# TLE986x register map
File version: 2.5
Registers are 32-bit, read-write, reset 0x0 unless marked. A register's access mark holds for its fields unless they carry their own. Offsets are from the block's base; [hi:lo] are bit positions; {n}, {i} and the like mark numbered series; 'fields as' and 'values as' point back to an identical list.

## BDRV
Base 0x40034000
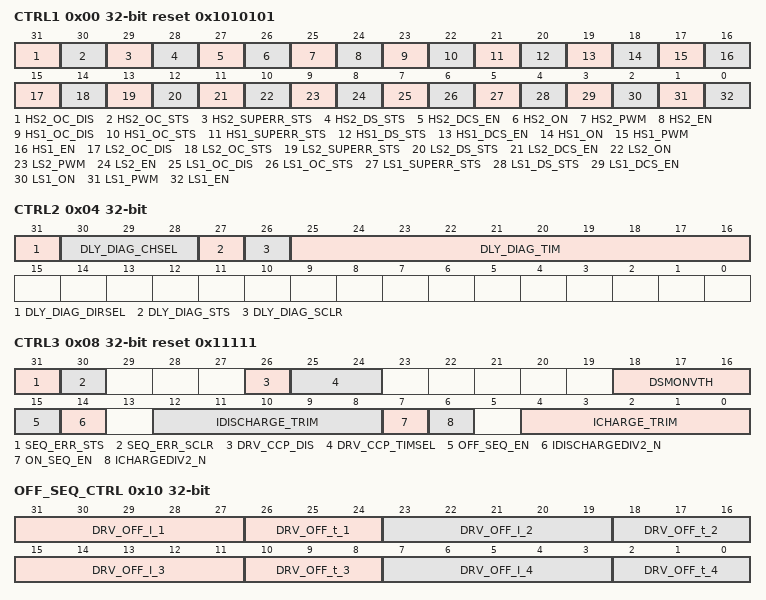
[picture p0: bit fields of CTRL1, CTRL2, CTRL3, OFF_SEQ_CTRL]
0x00 CTRL1 access per field reset 0x1010101 — H-Bridge Driver Control 1
  [31] HS2_OC_DIS rw — High Side Driver Overcurrent Shutdown Disable
    0=ENABLE (enable overcurrent shutdown of driver); 1=DISABLE (disable overcurrent shutdown of driver)
  [30] HS2_OC_STS ro — External High Side 2 FET Over-current Status
    0=no over-current Condition occurred; 1=over-current occurred; switch is automatically shutdown; write clear status
  [29] HS2_SUPERR_STS ro — High Side Driver 2 Supply Error Status
    0=NORMAL (supply is in required range.); 1=SUPPLY ERROR (detected; this flag is an OR of the VDS_x_STS and VCP_x_STS flags.)
  [28] HS2_DS_STS ro — High Side Driver 2 Drain Source Monitoring Status in OFF-State
    0=no short on external FET (no short detected.); 1=short on external FET detected (short detected; write clear status.)
  [27] HS2_DCS_EN rw — High Side Driver 2 Diagnosis Current Source Enable
    0=DISABLE (disable current source); 1=ENABLE (enable current source; short diagnosis can be performed by evaluating the LSx/HSx_DS_STS Flag)
  [26] HS2_ON rw — High Side Driver 2 On
    0=OFF (Driver off); 1=ON (Driver on)
  [25] HS2_PWM rw — High Side Driver 2 PWM Enable
    0=DISABLE (disables control by PWM input); 1=ENABLE (enables control by PWM input)
  [24] HS2_EN rw — High Side Driver 2 Enable
    0=DISABLE (Driver circuit power off); 1=ENABLE (Driver circuit power on)
  [23] HS1_OC_DIS rw — High Side Driver Overcurrent Shutdown Disable
    values as HS2_OC_DIS
  [22] HS1_OC_STS ro — External High Side 1 FET Over-current Status
    values as HS2_OC_STS
  [21] HS1_SUPERR_STS ro — High Side Driver 1 Supply Error Status
    values as HS2_SUPERR_STS
  [20] HS1_DS_STS ro — High Side Driver 1 Drain Source Monitoring Status in OFF-State
    values as HS2_DS_STS
  [19] HS1_DCS_EN rw — High Side Driver 1 Diagnosis Current Source Enable
    0=DISABLE (disable current source); 1=ENABLE (enable current source; short diagnosis can be performed by evaluating the LSx/HSx_SD_STS Flag)
  [18] HS1_ON rw — High Side Driver 1 On
    0=OFF (Driver off); 1=ON (Driver on)
  [17] HS1_PWM rw — High Side Driver 1 PWM Enable
    values as HS2_PWM
  [16] HS1_EN rw — High Side Driver 1 Enable
    values as HS2_EN
  [15] LS2_OC_DIS rw — Low Side Driver Overcurrent Shutdown Disable
    values as HS2_OC_DIS
  [14] LS2_OC_STS ro — External Low Side 2 FET Over-current Status
    values as HS2_OC_STS
  [13] LS2_SUPERR_STS ro — Low Side Driver 2 Supply Error Status
    values as HS2_SUPERR_STS
  [12] LS2_DS_STS ro — Low Side Driver 2 Drain Source Monitoring Status in OFF-State
    values as HS2_DS_STS
  [11] LS2_DCS_EN rw — Low Side Driver 2 Diagnosis Current Source Enable
    values as HS1_DCS_EN
  [10] LS2_ON rw — Low Side Driver 2 On
    0=OFF (Driver off); 1=ON (Driver on)
  [9] LS2_PWM rw — Low Side Driver 2 PWM Enable
    values as HS2_PWM
  [8] LS2_EN rw — Low Side Driver 2 Enable
    values as HS2_EN
  [7] LS1_OC_DIS rw — Low Side Driver 1 Overcurrent Shutdown Disable
    values as HS2_OC_DIS
  [6] LS1_OC_STS ro — External Low Side 1 FET Over-current Status
    values as HS2_OC_STS
  [5] LS1_SUPERR_STS ro — Low Side Driver 1 Supply Error Status
    values as HS2_SUPERR_STS
  [4] LS1_DS_STS ro — Low Side Driver 1 Drain Source Monitoring Status in OFF-State
    values as HS2_DS_STS
  [3] LS1_DCS_EN rw — Low Side Driver 1 Diagnosis Current Source Enable
    values as HS1_DCS_EN
  [2] LS1_ON rw — Low Side Driver 1 On
    0=OFF (Driver off); 1=ON (Driver on)
  [1] LS1_PWM rw — Low Side Driver 1 PWM Enable
    values as HS2_PWM
  [0] LS1_EN rw — Low Side Driver 1 Enable
    values as HS2_EN
0x04 CTRL2 access per field — H-Bridge Driver Control 2
  [31] DLY_DIAG_DIRSEL rw — Ext. power diag timer on / off select
    0=TURN OFF (measure turn on time); 1=TURN ON (measure turn off time)
  [30:28] DLY_DIAG_CHSEL rw — Ext. power on/off timer channel select
    0=DISABLE (diag timer deactivated.); 1=HB1 LS select (measure LS1 on/off delay time.); 2=HB2 LS select (measure LS2 on/off delay time.); 4=DISABLE (diag timer deactivated.); 5=HB1 HS select (measure HS1 on/off delay time.); 6=HB2 HS select (measure HS2 on/off delay time.)
  [27] DLY_DIAG_STS ro — Ext. power diag timer valid flag
    0=Diag timer invalid (diag timer measurement ongoing); 1=Diag timer valid (diag timer measurement finished)
  [26] DLY_DIAG_SCLR wo — Ext. power diag timer valid flag clear
    0=Diag timer valid not clear; 1=Diag timer valid clear
  [25:16] DLY_DIAG_TIM ro — Ext. power on/off diag timer result register
0x08 CTRL3 access per field reset 0x11111 — H-Bridge Driver Control 3
  [31] SEQ_ERR_STS ro — Driver Sequence Error Status
    0=Driver Sequence ok (no cross current); 1=Driver Sequence fail (HS and LS of same bridge concurrently activated, output protection activated)
  [30] SEQ_ERR_SCLR wo — Driver Sequence Error Status Clear
    0=Driver Sequence Status no clear; 1=Driver Sequence Status clear
  [26] DRV_CCP_DIS rw — Dynamic cross conduction protection Disable
    0=CCP Enable (dynamic ccp is active.); 1=CCP Disable (dynamic ccp is disabled, delayed gate clamp remains active.)
  [25:24] DRV_CCP_TIMSEL rw — minimum cross conduction protection time setting
    0=0.2us (200ns cross conduction protection time); 1=0.4us (400ns cross conduction protection time); 2=0.8us (800ns cross conduction protection time); 3=1.6us cross conduction protection time
  [18:16] DSMONVTH rw — Voltage Threshold for Drain-Source Monitoring of external FETs
    0=0.5_V (Threshold 0 for VDS at 0.5 V); 1=0.75_V (Threshold 1 for VDS at 0.75 V); 2=1.0_V (Threshold 2 for VDS at 1.0 V); 3=1.25_V (Threshold 3 for VDS at 1.25 V); 4=1.5_V (Threshold 4 for VDS at 1.5 V); 5=1.75_V (Threshold 5 for VDS at 1.75 V); 6=2.0_V (Threshold 6 for VDS at 2.0 V); 7=2.25_V (Threshold 7 for VDS at 2.25 V)
  [15] OFF_SEQ_EN rw — Turn Off Slewrate Sequencer enable
    0=Disabled (Turn Off Slewrate Sequencer disabled); 1=Enabled (Turn Off Slewrate Sequencer enabled)
  [14] IDISCHARGEDIV2_N rw — IDISCHARGE Current divide by 2 not
    0=Half Range (available for charge current (max. is 150 mA)); 1=Full Range (available for charge current (max. is 300 mA))
  [12:8] IDISCHARGE_TRIM rw — Trimming of the internal driver dis-charge current
    0=HiZ (Slew Rate Control is inactive); 1=min discharge rate (lowest gate charge current selected); 31=max discharge rate (max gate charge current is selected)
  [7] ON_SEQ_EN rw — Turn On SlewrateSequencer enable
    0=Disabled (Turn On Slewrate Sequencer disabled); 1=Enabled (Turn On Slewrate Sequencer enabled)
  [6] ICHARGEDIV2_N rw — ICHARGE Current divide by 2 not
    values as IDISCHARGEDIV2_N
  [4:0] ICHARGE_TRIM rw — Trimming of the internal driver charge current
    0=HiZ (Slew Rate Control is inactive); 1=min charge rate (lowest gate discharge current selected); 31=max charge rate (max gate discharge current is selected)
0x10 OFF_SEQ_CTRL — Turn on Slewrate Sequencer Control
  [39-8n:35-8n] DRV_OFF_I_{n} (n=1..4) — Slew rate sequencer off phase {n} current
    0=Disabled (Slew Rate Control is disabled); 31=maximum output discharge current
  [34-8n:32-8n] DRV_OFF_t_{n} (n=1..4) — Slew rate sequencer off phase {n} time
    0=50ns phase duration; 7=400ns phase duration
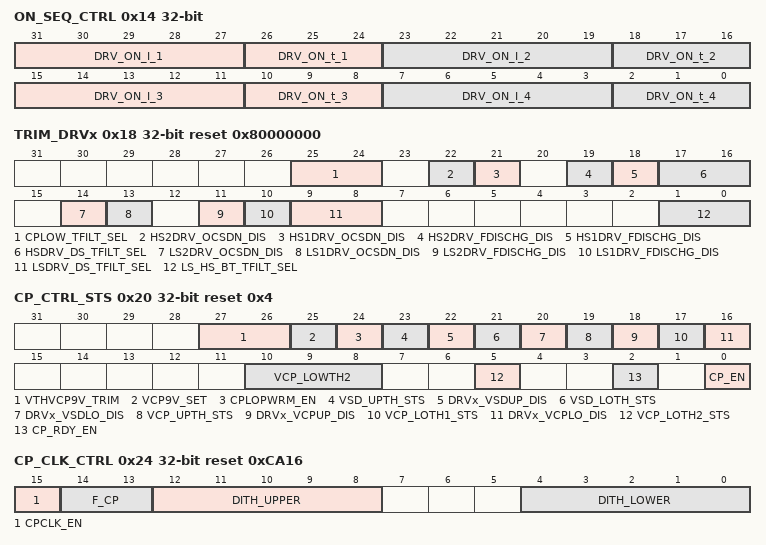
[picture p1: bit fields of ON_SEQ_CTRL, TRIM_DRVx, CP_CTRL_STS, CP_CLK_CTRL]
0x14 ON_SEQ_CTRL — Turn off Slewrate Sequencer Control
  [39-8n:35-8n] DRV_ON_I_{n} (n=1..4) — Slew rate sequencer on phase {n} current
    values as OFF_SEQ_CTRL.DRV_OFF_I_1
  [34-8n:32-8n] DRV_ON_t_{n} (n=1..4) — Slew rate sequencer on phase {n} time
    0=50ns phase duration; 7=400ns phase duration
0x18 TRIM_DRVx reset 0x80000000 — Trimming of Driver
  [25:24] CPLOW_TFILT_SEL — Filter Time for Charge Pump Voltage Low Diagnosis
    0=4 us filter time; 1=8 us filter time; 2=16 us filter time; 3=32 us filter time
  [22] HS2DRV_OCSDN_DIS — High Side 2 Predriver in overcurrent situation disable
    0=Enable (Predriver shutdown in overcurrent situation enable); 1=Disable (Predriver shutdown in overcurrent situation disable)
  [21] HS1DRV_OCSDN_DIS — High Side 1 Predriver in overcurrent situation disable
    values as HS2DRV_OCSDN_DIS
  [19] HS2DRV_FDISCHG_DIS — High Side 2 Predriver in overcurrent situation disable
    values as HS2DRV_OCSDN_DIS
  [18] HS1DRV_FDISCHG_DIS — High Side 1 Predriver in overcurrent situation disable
    values as HS2DRV_OCSDN_DIS
  [17:16] HSDRV_DS_TFILT_SEL — Filter Time for Drain-Source Monitoring of High Side Drivers
    0=1 us filter time; 1=2 us filter time; 2=4 us filter time; 3=8 us filter time
  [14] LS2DRV_OCSDN_DIS — Low Side 2 Predriver in overcurrent situation disable
    values as HS2DRV_OCSDN_DIS
  [13] LS1DRV_OCSDN_DIS — Low Side 1 Predriver in overcurrent situation disable
    values as HS2DRV_OCSDN_DIS
  [11] LS2DRV_FDISCHG_DIS — Low Side 2 Predriver in overcurrent situation disable
    values as HS2DRV_OCSDN_DIS
  [10] LS1DRV_FDISCHG_DIS — Low Side 1 Predriver in overcurrent situation disable
    values as HS2DRV_OCSDN_DIS
  [9:8] LSDRV_DS_TFILT_SEL — Filter Time for Drain-Source Monitoring of Low Side Drivers
    values as HSDRV_DS_TFILT_SEL
  [1:0] LS_HS_BT_TFILT_SEL — Blanking Time for Drain-Source Monitoring of Low / High Side Drivers
    values as HSDRV_DS_TFILT_SEL
0x20 CP_CTRL_STS access per field reset 0x4 — Charge Pump Control and Status Register
  [27:26] VTHVCP9V_TRIM rw — Charge Pump Output Voltage 9V Trimming
    0=7.5_V (Threshold 0); 1=8.0_V (Threshold 1); 2=8.5_V (Threshold 2); 3=9.0_V (Threshold 3)
  [25] VCP9V_SET rw — Charge Pump 9 V Output Voltage Set
    0=14V Set (output voltage set to 14V); 1=9V Set (output voltage set to 9V)
  [24] CPLOPWRM_EN rw — Charge Pump Low Power Mode Enable
    0=Low Power Mode Disable (low power mode inactive); 1=Low Power Mode Enable (low power mode active)
  [23] VSD_UPTH_STS ro — Driver Supply MU High Status
    0=Driver Supply Voltage ok (no overvoltage detected); 1=Driver Supply Voltage too high (overvoltage on VSD Pin detected)
  [22] DRVx_VSDUP_DIS rw — Driver On VSD Upper Voltage Disable
    0=Driver Enable (DRVx on VSD overvoltage enable.); 1=Driver Disable (DRVx on VSD overvoltage disable.)
  [21] VSD_LOTH_STS ro — Driver Supply MU Low Status
    0=Driver Supply Voltage ok (no undervoltage detected.); 1=Driver Supply Voltage too low (undervoltage on VSD Pin detected.)
  [20] DRVx_VSDLO_DIS rw — Driver On VSD Lower Voltage Disable
    0=Driver Enable (DRVx on VSD undervoltage enable.); 1=Driver Disable (DRVx on VSD undervoltage disable.)
  [19] VCP_UPTH_STS ro — Charge Pump MU High Status
    0=Charge Pump Output Voltage ok (no overvoltage detected); 1=Charge Pump Output Voltage too high (overvoltage on charge pump output detected)
  [18] DRVx_VCPUP_DIS rw — Driver On Charge Pump Upper Voltage Disable
    0=Driver Enable (DRVx on Charge Pumpe overvoltage enable.); 1=Driver Disable (DRVx on Charge Pump overvoltage disable.)
  [17] VCP_LOTH1_STS ro — Charge Pump MU Low Status
    0=Charge Pump Output Voltage ok (no undervoltage detected.); 1=Charge Pump Output Voltage too low (undervoltage on chargepump output detected.)
  [16] DRVx_VCPLO_DIS rw — Driver On Charge Pump Low Voltage Disable
    0=Driver Enable (DRVx on Charge Pump undervoltage enable.); 1=Driver Disable (DRVx on Charge Pump undervoltage disable.)
  [10:8] VCP_LOWTH2 rw — Charge Pump Output Voltage Lower Threshold Detection Level
    0=7.325_V (Threshold 0); 1=7.654_V (Threshold 1); 2=7.982_V (Threshold 2); 3=8.309_V (Threshold 3); 4=8.638_V (Threshold 4); 5=8.966_V (Threshold 5); 6=9.293_V (Threshold 6); 7=9.620_V (Threshold 7)
  [5] VCP_LOTH2_STS ro — Charge Pump Low Status
    values as VCP_LOTH1_STS
  [2] CP_RDY_EN rw — Bridge Driver on Charge Pump Ready Enable
    0=OFF (Bridge Driver can be immediately enabled); 1=ON (Bridge Driver can only be enabled when Charge Pump is ready)
  [0] CP_EN rw — Charge Pump Enable
    0=DISABLE (Charge Pump, circuit power off); 1=ENABLE (Charge Pump, circuit power on)
0x24 CP_CLK_CTRL reset 0xCA16 — Charge Pump Clock Control Register
  [15] CPCLK_EN — Charge Pump Clock Enable
    0=DISABLE (Charge Pump Clock is switched off and has value of 0); 1=ENABLE (Charge Pump Clock is running)
  [14:13] F_CP — MSB of CP_CLK divider
  [12:8] DITH_UPPER — CP_CLK upper frequency boundary during dithering
  [4:0] DITH_LOWER — CP_CLK lower frequency boundary during dithering
